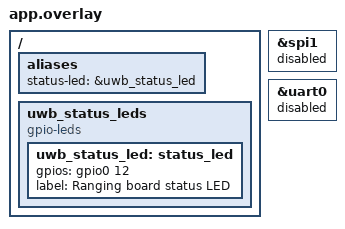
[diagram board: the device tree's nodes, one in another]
/ {
	aliases {
		status-led = &uwb_status_led;
	};

	uwb_status_leds {
		compatible = "gpio-leds";

		uwb_status_led: status_led {
			gpios = <&gpio0 12 GPIO_ACTIVE_HIGH>;
			label = "Ranging board status LED";
		};
	};
};

/* External DWM1001C SPI pins are connected to the ESP32-C3 on this PCB. */
&spi1 {
	status = "disabled";
};

/* Anchor firmware does not exchange telemetry with the ESP32-C3. */
&uart0 {
	status = "disabled";
};
